# STM32U5A5 register map
File version: 0.2
CPU: CM33 r0p1, little endian, MPU, FPU, 4 interrupt priority bits
Registers are 32-bit, read-write, reset 0x0 unless marked. A register's access mark holds for its fields unless they carry their own. Offsets are from the block's base; [hi:lo] are bit positions; {n}, {i} and the like mark numbered series.

## OTFDEC1 — On-The-Fly Decryption engine
Base 0x420C5000
Same registers: OTFDEC2 0x420C5400, SEC_OTFDEC1 0x520C5000, SEC_OTFDEC2 0x520C5400
0x00 CR — OTFDEC control register
  [0] ENC — Encryption mode bit
0x10 PRIVCFGR — OTFDEC privileged access control configuration register
  [0] PRIV — Encryption mode bit
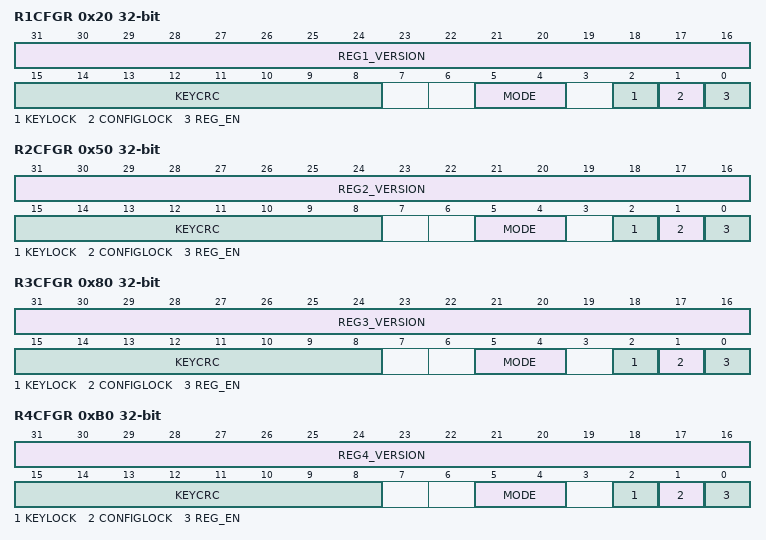
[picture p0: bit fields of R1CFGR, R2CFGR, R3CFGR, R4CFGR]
0x20 R1CFGR access per field — OTFDEC region x configuration register
  [31:16] REG1_VERSION rw — region firmware version
  [15:8] KEYCRC ro — region key 8-bit CRC
  [5:4] MODE rw — operating mode
  [2] KEYLOCK rw — region key lock
  [1] CONFIGLOCK rw — region config lock
  [0] REG_EN rw — region on-the-fly decryption enable
0x24 R1STARTADDR — OTFDEC region x start address register
  [31:0] REG1_START_ADDR — Region AXI start address
0x28 R1ENDADDR reset 0xFFF — OTFDEC region x end address register
  [31:0] REG1_END_ADDR — Region AXI end address
0x2C R1NONCER0 — OTFDEC region x nonce register 0
  [31:0] REG1_NONCE
0x30 R1NONCER1 — OTFDEC region x nonce register 1
  [31:0] REG1_NONCE — Region nonce
{0x4+0x30*i} R{i}KEYR0 wo (i=1..4) — OTFDEC region x key register 0
  [31:0] REG{i}_KEY
{0x8+0x30*i} R{i}KEYR1 wo (i=1..4) — OTFDEC region x key register 1
  [31:0] REG{i}_KEY
0x3C R1KEYR2 wo — OTFDEC region x key register 2
  [31:0] REG1_KEY
{0x10+0x30*i} R{i}KEYR3 wo (i=1..4) — OTFDEC region x key register 3
  [31:0] REG{i}_KEY
0x50 R2CFGR access per field — OTFDEC region x configuration register
  [31:16] REG2_VERSION rw — region firmware version
  [15:8] KEYCRC ro — region key 8-bit CRC
  [5:4] MODE rw — operating mode
  [2] KEYLOCK rw — region key lock
  [1] CONFIGLOCK rw — region config lock
  [0] REG_EN rw — region on-the-fly decryption enable
0x54 R2STARTADDR — OTFDEC region x start address register
  [31:0] REG2_START_ADDR — Region AXI start address
0x58 R2ENDADDR reset 0xFFF — OTFDEC region x end address register
  [31:0] REG2_END_ADDR — Region AXI end address
0x5C R2NONCER0 — OTFDEC region x nonce register 0
  [31:0] REG2_NONCE
0x60 R2NONCER1 — OTFDEC region x nonce register 1
  [31:0] REG2_NONCE — Region nonce, bits [63:32]REGx_NONCE[63:32]
0x6C R2KEYR2 wo — OTFDEC region x key register 2
  [31:0] REG2_KEY_
0x80 R3CFGR access per field — OTFDEC region x configuration register
  [31:16] REG3_VERSION rw — region firmware version
  [15:8] KEYCRC ro — region key 8-bit CRC
  [5:4] MODE rw — operating mode
  [2] KEYLOCK rw — region key lock
  [1] CONFIGLOCK rw — region config lock
  [0] REG_EN rw — region on-the-fly decryption enable
0x84 R3STARTADDR — OTFDEC region x start address register
  [31:0] REG3_START_ADDR — Region AXI start address
0x88 R3ENDADDR reset 0xFFF — OTFDEC region x end address register
  [31:0] REG3_END_ADDR — Region AXI end address
0x8C R3NONCER0 (alternate view of R4ENDADDR) — OTFDEC region x nonce register 0
  [31:0] REG3_NONCE
0x90 R3NONCER1 — OTFDEC region x nonce register 1
  [31:0] REG3_NONCE
0x9C R3KEYR2 wo — OTFDEC region x key register 2
  [31:0] REG3_KEY
0xB0 R4CFGR access per field — OTFDEC region x configuration register
  [31:16] REG4_VERSION rw — region firmware version
  [15:8] KEYCRC ro — region key 8-bit CRC
  [5:4] MODE rw — operating mode
  [2] KEYLOCK rw — region key lock
  [1] CONFIGLOCK rw — region config lock
  [0] REG_EN rw — region on-the-fly decryption enable
0xB4 R4STARTADDR — OTFDEC region x start address register
  [31:0] REG4_START_ADDR — Region AXI start address
0xB8 R4ENDADDR reset 0xFFF — OTFDEC region x end address register
  [31:0] REG4_END_ADDR — Region AXI end address
0xBC R4NONCER0 — OTFDEC region x nonce register 0
  [31:0] REG4_NONCE
0xC0 R4NONCER1 — OTFDEC region x nonce register 1
  [31:0] REG4_NONCE
0xCC R4KEYR2 wo — OTFDEC region x key register 2
  [31:0] REG4_KEY
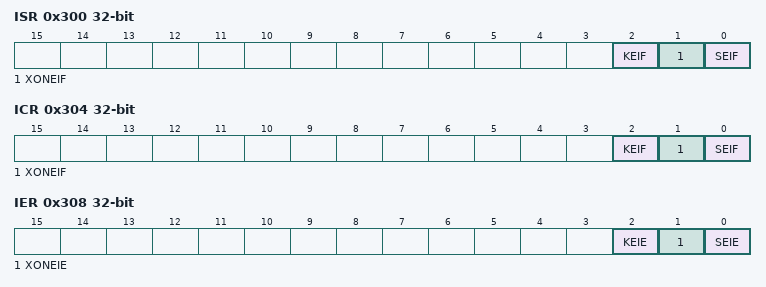
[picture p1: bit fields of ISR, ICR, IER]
0x300 ISR ro — OTFDEC interrupt status register
  [2] KEIF — Key Error Interrupt Flag status
  [1] XONEIF — Execute-only execute-Never Error Interrupt Flag status
  [0] SEIF — Security Error Interrupt Flag status
0x304 ICR ro — OTFDEC interrupt clear register
  [2] KEIF
  [1] XONEIF — Execute-only execute-Never Error Interrupt Flag clear
  [0] SEIF
0x308 IER — OTFDEC interrupt enable register
  [2] KEIE
  [1] XONEIE
  [0] SEIE — Security Error Interrupt Enable
